# ESP32S31_RADIO register map
Vendor: Espressif; Series: ESP32-S31; File version: 3.52
Registers are 32-bit, read-write, no defined reset value unless marked. A register's access mark holds for its fields unless they carry their own. Offsets are from the block's base; [hi:lo] are bit positions.

## WIFI_MAC_RX_DMA — Descriptor-walker registers recovered from complete rev0 ROM leaves and qualified with the open driver's rotating 32-entry RX ring.
Base 0x20104000
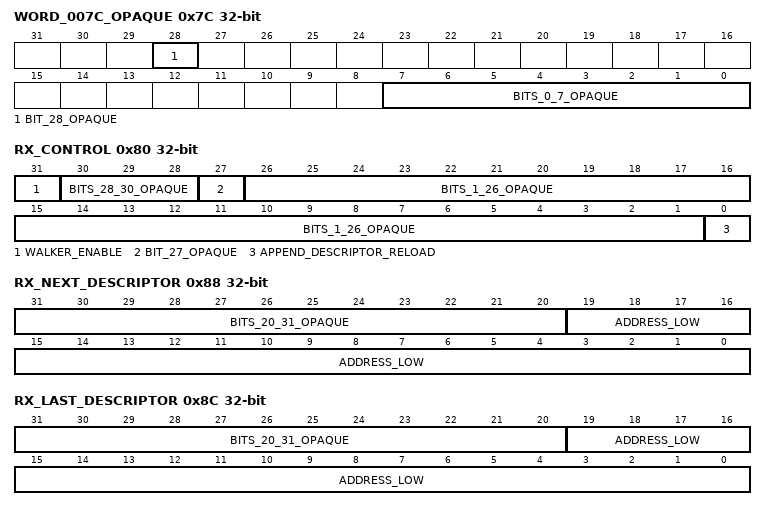
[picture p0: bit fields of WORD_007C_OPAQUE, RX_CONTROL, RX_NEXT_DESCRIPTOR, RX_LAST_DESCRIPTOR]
0x7C WORD_007C_OPAQUE — Opaque: meaning not established. Complete mac_rxbuf_init clears the low byte immediately before publishing the descriptor base. Individual bit meanings are unknown.
  [28] BIT_28_OPAQUE — Opaque: meaning not established. Observed source use; the individual hardware meaning is unknown.
  [7:0] BITS_0_7_OPAQUE — Opaque: meaning not established.
0x80 RX_CONTROL — Project-assigned name. RX descriptor-walker gate, hardware-beacon reload selection and live-list append doorbell.
  [31] WALKER_ENABLE — Project-assigned name. Set by libpp[hal_mac.o]::hal_mac_rx_enable and cleared by libpp[hal_mac.o]::hal_mac_rx_disable; gates the RX descriptor walker.
  [30:28] BITS_28_30_OPAQUE — Opaque: meaning not established. Observed source use; the individual hardware meaning is unknown.
  [27] BIT_27_OPAQUE — Opaque: meaning not established. Complete hal_mac_set_rxbuf_reload_use_hw_beacon_enable sets bit 27 through one fresh-read RMW.
  [26:1] BITS_1_26_OPAQUE — Opaque: meaning not established. Observed source use; the individual hardware meaning is unknown.
  [0] APPEND_DESCRIPTOR_RELOAD write-clears — Project-assigned name. Write one after publishing old_tail.next to make a prepared live-list append visible. Hardware clears the bit after accepting the append.
0x84 RX_DESCRIPTOR_BASE — Project-assigned name. Complete first-descriptor address. The ROM and blob leaves publish the unmasked 32-bit pointer when installing a cold or repaired frontier; the selected high-address window separately completes the hardware last/next descriptor observations.
  [31:0] ADDRESS — Project-assigned name.
0x88 RX_NEXT_DESCRIPTOR ro — Project-assigned name. Complete hardware current/next descriptor word. The low 20 bits are the reviewed address projection; meanings of bits 31:20 remain unknown. Complete ROM rom[]::wDev_AppendRxBlocks compares the entire 32-bit word with zero after reload completion, not only ADDRESS_LOW, before it may read LAST and repair RX_DESCRIPTOR_BASE.
  [31:20] BITS_20_31_OPAQUE — Opaque: meaning not established. Unassigned upper state retained by the complete-word zero predicate in rom[]::wDev_AppendRxBlocks. This is deliberately exposed separately from ADDRESS_LOW so production code never reconstructs or masks a register image.
  [19:0] ADDRESS_LOW — Project-assigned name.
0x8C RX_LAST_DESCRIPTOR ro — Project-assigned name. Low 20 bits of the last descriptor accepted by the RX walker.
  [31:20] BITS_20_31_OPAQUE — Opaque: meaning not established. Observed source use; the individual hardware meaning is unknown.
  [19:0] ADDRESS_LOW — Project-assigned name.
0xC68 WORD_0C68_OPAQUE — Opaque: meaning not established. Complete mac_rxbuf_init sets the low twenty bits before descriptor publication.
  [19:0] BITS_0_19_OPAQUE — Opaque: meaning not established.
0xC6C WORD_0C6C_OPAQUE — Opaque: meaning not established. Complete mac_rxbuf_init replaces the low twenty bits with four before selecting the descriptor high window.
  [19:0] BITS_0_19_OPAQUE — Opaque: meaning not established.
0xC70 RX_DESCRIPTOR_HIGH_WINDOW — Project-assigned name. High 12 descriptor-address bits shared with the low-address RX pointer registers. Complete mac_rxbuf_init and the open driver program 0x2f0 for internal SRAM.
  [31:20] ADDRESS_HIGH — Project-assigned name.

## WIFI_MAC_CSI_DUMP — The CSI dump configuration word beside the RX descriptor walker, at the same base.
Base 0x20104000
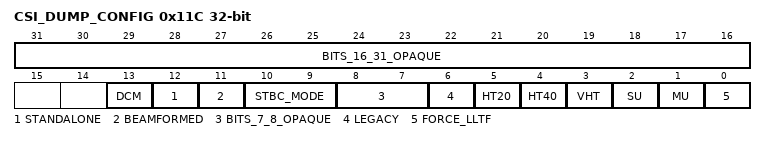
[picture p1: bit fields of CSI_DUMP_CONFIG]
0x11C CSI_DUMP_CONFIG — Project-assigned name. Complete esp_test_get_csi_dump_cfg reads every described field at 0x2010411c. Complete esp_test_set_csi_dump_cfg performs independent fresh-read RMW updates. Its BEAMFORMED update has a pinned vendor quirk: cfg[8] controls whether bit 11 is updated, but cfg[1] (MU) supplies the value. This SVD exposes the physical bit and does not reproduce that software bug.
  [31:16] BITS_16_31_OPAQUE — Opaque: meaning not established. Observed source use; the individual hardware meaning is unknown.
  [13] DCM — Project-assigned name.
  [12] STANDALONE — Project-assigned name.
  [11] BEAMFORMED — Project-assigned name. Physical CSI-dump beamformed selector. The pinned vendor setter accidentally writes the MU argument when this field is selected; callers of the generated PAC write the actual bit directly.
  [10:9] STBC_MODE — Project-assigned name.
  [8:7] BITS_7_8_OPAQUE — Opaque: meaning not established. Observed source use; the individual hardware meaning is unknown.
  [6] LEGACY — Project-assigned name.
  [5] HT20 — Project-assigned name.
  [4] HT40 — Project-assigned name.
  [3] VHT — Project-assigned name.
  [2] SU — Project-assigned name.
  [1] MU — Project-assigned name.
  [0] FORCE_LLTF — Project-assigned name.
